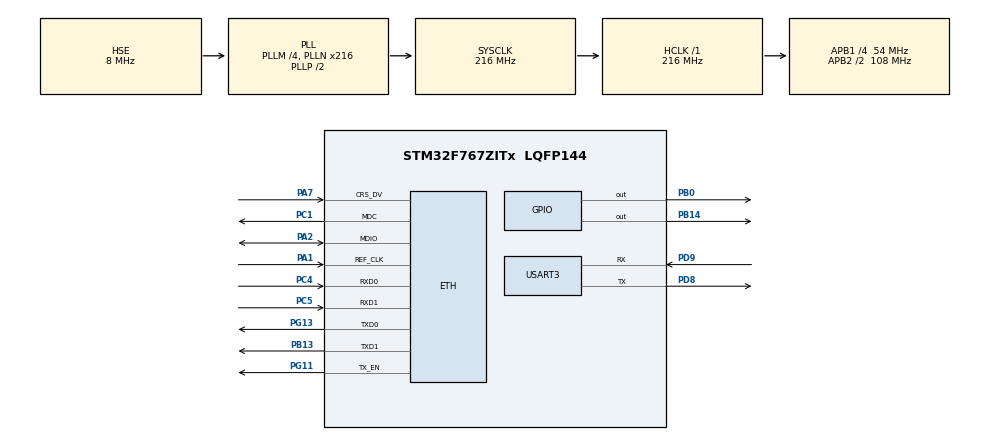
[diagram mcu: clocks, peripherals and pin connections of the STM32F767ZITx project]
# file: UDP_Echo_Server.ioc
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CORTEX_M7.AccessPermission-Cortex_Memory_Protection_Unit_Region1_Settings=MPU_REGION_FULL_ACCESS
CORTEX_M7.AccessPermission-Cortex_Memory_Protection_Unit_Region2_Settings=MPU_REGION_FULL_ACCESS
CORTEX_M7.BaseAddress-Cortex_Memory_Protection_Unit_Region1_Settings=0x20060000
CORTEX_M7.BaseAddress-Cortex_Memory_Protection_Unit_Region2_Settings=0x20060000
CORTEX_M7.CPU_DCache=Enabled
CORTEX_M7.CPU_ICache=Enabled
CORTEX_M7.DisableExec-Cortex_Memory_Protection_Unit_Region0_Settings=MPU_INSTRUCTION_ACCESS_DISABLE
CORTEX_M7.DisableExec-Cortex_Memory_Protection_Unit_Region1_Settings=MPU_INSTRUCTION_ACCESS_DISABLE
CORTEX_M7.DisableExec-Cortex_Memory_Protection_Unit_Region2_Settings=MPU_INSTRUCTION_ACCESS_DISABLE
CORTEX_M7.Enable-Cortex_Memory_Protection_Unit_Region0_Settings=MPU_REGION_ENABLE
CORTEX_M7.Enable-Cortex_Memory_Protection_Unit_Region1_Settings=MPU_REGION_ENABLE
CORTEX_M7.Enable-Cortex_Memory_Protection_Unit_Region2_Settings=MPU_REGION_ENABLE
CORTEX_M7.IsShareable-Cortex_Memory_Protection_Unit_Region0_Settings=MPU_ACCESS_SHAREABLE
CORTEX_M7.MPU_Control=MPU_PRIVILEGED_DEFAULT
CORTEX_M7.Size-Cortex_Memory_Protection_Unit_Region0_Settings=MPU_REGION_SIZE_4GB
CORTEX_M7.Size-Cortex_Memory_Protection_Unit_Region1_Settings=MPU_REGION_SIZE_32KB
CORTEX_M7.Size-Cortex_Memory_Protection_Unit_Region2_Settings=MPU_REGION_SIZE_512B
CORTEX_M7.SubRegionDisable-Cortex_Memory_Protection_Unit_Region0_Settings=0x87
ETH.MediaInterface=HAL_ETH_RMII_MODE
Mcu.Family=STM32F7
Mcu.Name=STM32F767ZITx
Mcu.Package=LQFP144
NVIC.ETH_IRQn=true\:7\:0\:true\:false\:true\:false\:true\:true\:true
NVIC.PriorityGroup=NVIC_PRIORITYGROUP_4
NVIC.TIM6_DAC_IRQn=true\:15\:0\:false\:false\:true\:false\:false\:true\:true
NVIC.TimeBase=TIM6_DAC_IRQn
NVIC.TimeBaseIP=TIM6
PA1.Mode=RMII
PA1.Signal=ETH_REF_CLK
PA2.Mode=RMII
PA2.Signal=ETH_MDIO
PA7.Mode=RMII
PA7.Signal=ETH_CRS_DV
PB0.GPIO_Speed=GPIO_SPEED_FREQ_VERY_HIGH
PB0.Signal=GPIO_Output
PB13.Mode=RMII
PB13.Signal=ETH_TXD1
PB14.GPIO_Speed=GPIO_SPEED_FREQ_VERY_HIGH
PB14.Signal=GPIO_Output
PC1.Mode=RMII
PC1.Signal=ETH_MDC
PC4.Mode=RMII
PC4.Signal=ETH_RXD0
PC5.Mode=RMII
PC5.Signal=ETH_RXD1
PD8.Mode=Asynchronous
PD8.Signal=USART3_TX
PD9.Mode=Asynchronous
PD9.Signal=USART3_RX
PG11.Mode=RMII
PG11.Signal=ETH_TX_EN
PG13.Mode=RMII
PG13.Signal=ETH_TXD0
PH0/OSC_IN.Mode=HSE-External-Clock-Source
PH0/OSC_IN.Signal=RCC_OSC_IN
PH1/OSC_OUT.Mode=HSE-External-Clock-Source
PH1/OSC_OUT.Signal=RCC_OSC_OUT
ProjectManager.HeapSize=0x200
ProjectManager.StackSize=0x400
ProjectManager.TargetToolchain=STM32CubeIDE
RCC.AHBFreq_Value=216000000
RCC.APB1CLKDivider=RCC_HCLK_DIV4
RCC.APB1Freq_Value=54000000
RCC.APB1TimFreq_Value=108000000
RCC.APB2CLKDivider=RCC_HCLK_DIV2
RCC.APB2Freq_Value=108000000
RCC.APB2TimFreq_Value=216000000
RCC.CortexFreq_Value=216000000
RCC.HCLKFreq_Value=216000000
RCC.HSE_VALUE=8000000
RCC.HSI_VALUE=16000000
RCC.LSE_VALUE=32768
RCC.PLLM=4
RCC.PLLN=216
RCC.PLLSourceVirtual=RCC_PLLSOURCE_HSE
RCC.SYSCLKFreq_VALUE=216000000
RCC.SYSCLKSource=RCC_SYSCLKSOURCE_PLLCLK
RCC.USBFreq_Value=216000000
RCC.VCOOutputFreq_Value=432000000
STMicroelectronics.X-CUBE-AZRTOS-F7.1.1.0.InterfacesCcNetworkJjEthernetOoInterface=true
STMicroelectronics.X-CUBE-AZRTOS-F7.1.1.0.InterfacesCcNetworkJjEthernetOoPhyOoInterface=LAN8742IiPhyIiInterface
STMicroelectronics.X-CUBE-AZRTOS-F7.1.1.0.NX_APP_MEM_POOL_SIZE=30 * 1024
STMicroelectronics.X-CUBE-AZRTOS-F7.1.1.0.NetXDuoCcNetworkJjNetXDuoJjAddonsOoDHCPOoClient=true
STMicroelectronics.X-CUBE-AZRTOS-F7.1.1.0.NetXDuoCcNetworkJjNetXDuoJjNXOoCore=true
STMicroelectronics.X-CUBE-AZRTOS-F7.1.1.0.STM32CubeIiBSPIiComponentsCcBoardOoPartJjETHPhyJjLAN8742=true
STMicroelectronics.X-CUBE-AZRTOS-F7.1.1.0.ThreadXCcRTOSJjThreadXJjCore=true
STMicroelectronics.X-CUBE-AZRTOS-F7.1.1.0_IsAnAzureRtosMw=true
USART3.VirtualMode-Asynchronous=VM_ASYNC
VP_STMicroelectronics.X-CUBE-AZRTOS-F7_VS_BoardOoPartJjSTM32CubeIiBSPIiComponents_1.1.0_1.1.0.Mode=BoardOoPartJjSTM32CubeIiBSPIiComponents
VP_STMicroelectronics.X-CUBE-AZRTOS-F7_VS_NetworkJjInterfaces_2.1.0_1.1.0.Mode=NetworkJjInterfaces
VP_STMicroelectronics.X-CUBE-AZRTOS-F7_VS_NetworkJjNetXDuo_6.1.10_1.1.0.Mode=NetworkJjNetXDuo
VP_STMicroelectronics.X-CUBE-AZRTOS-F7_VS_RTOSJjThreadX_6.1.10_1.1.0.Mode=RTOSJjThreadX
VP_SYS_VS_tim6.Mode=TIM6
board=custom

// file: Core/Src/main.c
/* USER CODE BEGIN Header */
/**
  ******************************************************************************
  * @file           : main.c
  * @brief          : Main program body
  ******************************************************************************
  * @attention
  *
  * Copyright (c) 2022 STMicroelectronics.
  * All rights reserved.
  *
  * This software is licensed under terms that can be found in the LICENSE file
  * in the root directory of this software component.
  * If no LICENSE file comes with this software, it is provided AS-IS.
  *
  ******************************************************************************
  */
/* USER CODE END Header */
#include "main.h"
#include "string.h"
#include "app_threadx.h"

/* USER CODE BEGIN PM */
#if defined ( __GNUC__) && !defined(__clang__)
/* With GCC, small printf (option LD Linker->Libraries->Small printf
   set to 'Yes') calls __io_putchar() */
#define PUTCHAR_PROTOTYPE int __io_putchar(int ch)
#else
#define PUTCHAR_PROTOTYPE int fputc(int ch, FILE *f)
#endif

/* USER CODE END PM */

#if defined ( __ICCARM__ ) /*!< IAR Compiler */
#pragma location=0x2007c000
ETH_DMADescTypeDef  DMARxDscrTab[ETH_RX_DESC_CNT]; /* Ethernet Rx DMA Descriptors */
#pragma location=0x2007c0a0
ETH_DMADescTypeDef  DMATxDscrTab[ETH_TX_DESC_CNT]; /* Ethernet Tx DMA Descriptors */

#elif defined ( __CC_ARM )  /* MDK ARM Compiler */

__attribute__((at(0x2007c000))) ETH_DMADescTypeDef  DMARxDscrTab[ETH_RX_DESC_CNT]; /* Ethernet Rx DMA Descriptors */
__attribute__((at(0x2007c0a0))) ETH_DMADescTypeDef  DMATxDscrTab[ETH_TX_DESC_CNT]; /* Ethernet Tx DMA Descriptors */

#elif defined ( __GNUC__ ) /* GNU Compiler */
ETH_DMADescTypeDef DMARxDscrTab[ETH_RX_DESC_CNT] __attribute__((section(".RxDecripSection"))); /* Ethernet Rx DMA Descriptors */
ETH_DMADescTypeDef DMATxDscrTab[ETH_TX_DESC_CNT] __attribute__((section(".TxDecripSection")));   /* Ethernet Tx DMA Descriptors */

#endif

ETH_TxPacketConfig TxConfig;

ETH_HandleTypeDef heth;

UART_HandleTypeDef huart3;

void SystemClock_Config(void);
static void MPU_Config(void);
static void MX_GPIO_Init(void);
static void MX_ETH_Init(void);
static void MX_USART3_UART_Init(void);

int main(void)
{

  /* MPU Configuration--------------------------------------------------------*/
  MPU_Config();

  /* Enable I-Cache---------------------------------------------------------*/
  SCB_EnableICache();

  /* Enable D-Cache---------------------------------------------------------*/
  SCB_EnableDCache();

  /* MCU Configuration--------------------------------------------------------*/

  /* Reset of all peripherals, Initializes the Flash interface and the Systick. */
  HAL_Init();

  /* Configure the system clock */
  SystemClock_Config();

  /* Initialize all configured peripherals */
  MX_GPIO_Init();
  MX_ETH_Init();
  MX_USART3_UART_Init();

  MX_ThreadX_Init();

  /* We should never get here as control is now taken by the scheduler */
  /* Infinite loop */
  while (1)
  {

  }
}

void SystemClock_Config(void)
{
  RCC_OscInitTypeDef RCC_OscInitStruct = {0};
  RCC_ClkInitTypeDef RCC_ClkInitStruct = {0};

  /** Configure the main internal regulator output voltage
  */
  __HAL_RCC_PWR_CLK_ENABLE();
  __HAL_PWR_VOLTAGESCALING_CONFIG(PWR_REGULATOR_VOLTAGE_SCALE1);

  /** Initializes the RCC Oscillators according to the specified parameters
  * in the RCC_OscInitTypeDef structure.
  */
  RCC_OscInitStruct.OscillatorType = RCC_OSCILLATORTYPE_HSE;
  RCC_OscInitStruct.HSEState = RCC_HSE_BYPASS;
  RCC_OscInitStruct.PLL.PLLState = RCC_PLL_ON;
  RCC_OscInitStruct.PLL.PLLSource = RCC_PLLSOURCE_HSE;
  RCC_OscInitStruct.PLL.PLLM = 4;
  RCC_OscInitStruct.PLL.PLLN = 216;
  RCC_OscInitStruct.PLL.PLLP = RCC_PLLP_DIV2;
  RCC_OscInitStruct.PLL.PLLQ = 2;
  RCC_OscInitStruct.PLL.PLLR = 2;
  if (HAL_RCC_OscConfig(&RCC_OscInitStruct) != HAL_OK)
  {
    Error_Handler();
  }

  /** Activate the Over-Drive mode
  */
  if (HAL_PWREx_EnableOverDrive() != HAL_OK)
  {
    Error_Handler();
  }

  /** Initializes the CPU, AHB and APB buses clocks
  */
  RCC_ClkInitStruct.ClockType = RCC_CLOCKTYPE_HCLK|RCC_CLOCKTYPE_SYSCLK
                              |RCC_CLOCKTYPE_PCLK1|RCC_CLOCKTYPE_PCLK2;
  RCC_ClkInitStruct.SYSCLKSource = RCC_SYSCLKSOURCE_PLLCLK;
  RCC_ClkInitStruct.AHBCLKDivider = RCC_SYSCLK_DIV1;
  RCC_ClkInitStruct.APB1CLKDivider = RCC_HCLK_DIV4;
  RCC_ClkInitStruct.APB2CLKDivider = RCC_HCLK_DIV2;

  if (HAL_RCC_ClockConfig(&RCC_ClkInitStruct, FLASH_LATENCY_7) != HAL_OK)
  {
    Error_Handler();
  }
}

static void MX_ETH_Init(void)
{

   static uint8_t MACAddr[6];

  heth.Instance = ETH;
  MACAddr[0] = 0x00;
  MACAddr[1] = 0x80;
  MACAddr[2] = 0xE1;
  MACAddr[3] = 0x00;
  MACAddr[4] = 0x00;
  MACAddr[5] = 0x00;
  heth.Init.MACAddr = &MACAddr[0];
  heth.Init.MediaInterface = HAL_ETH_RMII_MODE;
  heth.Init.TxDesc = DMATxDscrTab;
  heth.Init.RxDesc = DMARxDscrTab;
  heth.Init.RxBuffLen = 1536;

  if (HAL_ETH_Init(&heth) != HAL_OK)
  {
    Error_Handler();
  }

  memset(&TxConfig, 0 , sizeof(ETH_TxPacketConfig));
  TxConfig.Attributes = ETH_TX_PACKETS_FEATURES_CSUM | ETH_TX_PACKETS_FEATURES_CRCPAD;
  TxConfig.ChecksumCtrl = ETH_CHECKSUM_IPHDR_PAYLOAD_INSERT_PHDR_CALC;
  TxConfig.CRCPadCtrl = ETH_CRC_PAD_INSERT;

}

static void MX_USART3_UART_Init(void)
{

  huart3.Instance = USART3;
  huart3.Init.BaudRate = 115200;
  huart3.Init.WordLength = UART_WORDLENGTH_8B;
  huart3.Init.StopBits = UART_STOPBITS_1;
  huart3.Init.Parity = UART_PARITY_NONE;
  huart3.Init.Mode = UART_MODE_TX_RX;
  huart3.Init.HwFlowCtl = UART_HWCONTROL_NONE;
  huart3.Init.OverSampling = UART_OVERSAMPLING_16;
  huart3.Init.OneBitSampling = UART_ONE_BIT_SAMPLE_DISABLE;
  huart3.AdvancedInit.AdvFeatureInit = UART_ADVFEATURE_NO_INIT;
  if (HAL_UART_Init(&huart3) != HAL_OK)
  {
    Error_Handler();
  }

}

static void MX_GPIO_Init(void)
{
  GPIO_InitTypeDef GPIO_InitStruct = {0};

  /* GPIO Ports Clock Enable */
  __HAL_RCC_GPIOH_CLK_ENABLE();
  __HAL_RCC_GPIOC_CLK_ENABLE();
  __HAL_RCC_GPIOA_CLK_ENABLE();
  __HAL_RCC_GPIOB_CLK_ENABLE();
  __HAL_RCC_GPIOD_CLK_ENABLE();
  __HAL_RCC_GPIOG_CLK_ENABLE();

  /*Configure GPIO pin Output Level */
  HAL_GPIO_WritePin(GPIOB, GPIO_PIN_0|GPIO_PIN_14, GPIO_PIN_RESET);

  /*Configure GPIO pins : PB0 PB14 */
  GPIO_InitStruct.Pin = GPIO_PIN_0|GPIO_PIN_14;
  GPIO_InitStruct.Mode = GPIO_MODE_OUTPUT_PP;
  GPIO_InitStruct.Pull = GPIO_NOPULL;
  GPIO_InitStruct.Speed = GPIO_SPEED_FREQ_VERY_HIGH;
  HAL_GPIO_Init(GPIOB, &GPIO_InitStruct);

}

/* USER CODE BEGIN 4 */
PUTCHAR_PROTOTYPE
{
  /* Place your implementation of fputc here */
  /* e.g. write a character to the USART1 and Loop until the end of transmission */
  HAL_UART_Transmit(&huart3, (uint8_t *)&ch, 1, 0xFFFF);

  return ch;
}

/* USER CODE END 4 */

/* MPU Configuration */

void MPU_Config(void)
{
  MPU_Region_InitTypeDef MPU_InitStruct = {0};

  /* Disables the MPU */
  HAL_MPU_Disable();

  /** Initializes and configures the Region and the memory to be protected
  */
  MPU_InitStruct.Enable = MPU_REGION_ENABLE;
  MPU_InitStruct.Number = MPU_REGION_NUMBER0;
  MPU_InitStruct.BaseAddress = 0x0;
  MPU_InitStruct.Size = MPU_REGION_SIZE_4GB;
  MPU_InitStruct.SubRegionDisable = 0x87;
  MPU_InitStruct.TypeExtField = MPU_TEX_LEVEL0;
  MPU_InitStruct.AccessPermission = MPU_REGION_NO_ACCESS;
  MPU_InitStruct.DisableExec = MPU_INSTRUCTION_ACCESS_DISABLE;
  MPU_InitStruct.IsShareable = MPU_ACCESS_SHAREABLE;
  MPU_InitStruct.IsCacheable = MPU_ACCESS_NOT_CACHEABLE;
  MPU_InitStruct.IsBufferable = MPU_ACCESS_NOT_BUFFERABLE;

  HAL_MPU_ConfigRegion(&MPU_InitStruct);

  /** Initializes and configures the Region and the memory to be protected
  */
  MPU_InitStruct.Number = MPU_REGION_NUMBER1;
  MPU_InitStruct.BaseAddress = 0x20060000;
  MPU_InitStruct.Size = MPU_REGION_SIZE_32KB;
  MPU_InitStruct.SubRegionDisable = 0x0;
  MPU_InitStruct.AccessPermission = MPU_REGION_FULL_ACCESS;
  MPU_InitStruct.IsShareable = MPU_ACCESS_NOT_SHAREABLE;

  HAL_MPU_ConfigRegion(&MPU_InitStruct);

  /** Initializes and configures the Region and the memory to be protected
  */
  MPU_InitStruct.Number = MPU_REGION_NUMBER2;
  MPU_InitStruct.Size = MPU_REGION_SIZE_512B;

  HAL_MPU_ConfigRegion(&MPU_InitStruct);
  /* Enables the MPU */
  HAL_MPU_Enable(MPU_PRIVILEGED_DEFAULT);

}

void HAL_TIM_PeriodElapsedCallback(TIM_HandleTypeDef *htim)
{
  if (htim->Instance == TIM6) {
    HAL_IncTick();
  }
}

void Error_Handler(void)
{
  /* USER CODE BEGIN Error_Handler_Debug */
  /* User can add his own implementation to report the HAL error return state */
	HAL_GPIO_WritePin(GPIOB, GPIO_PIN_0, GPIO_PIN_RESET);
	while (1)
	{
		HAL_GPIO_TogglePin(GPIOB, GPIO_PIN_14);
		HAL_Delay(200);
	}

  /* USER CODE END Error_Handler_Debug */
}
